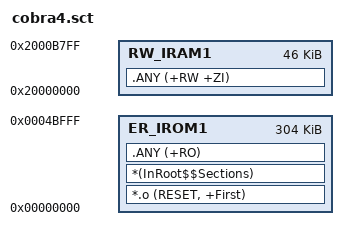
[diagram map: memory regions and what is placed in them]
#! armcc -E -I  .\  --cpu Cortex-M4

#include "cobra_config.h"
	
LR_IROM1 0x00000000 0x0004C000  {    ; load region size_region
  ER_IROM1 0x00000000 0x0004C000   {  ; load address = execution address
   *.o (RESET, +First)
   *(InRoot$$Sections)
   .ANY (+RO)
  }
  
  RW_IRAM1 0x20000000 0x0000b800  {  ; RW data
   .ANY (+RW +ZI)
  }
	 
}




